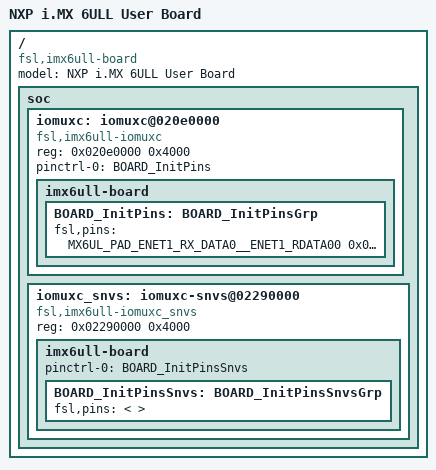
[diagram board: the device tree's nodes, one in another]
/***********************************************************************************************************************
 * This file was generated by the MCUXpresso Config Tools. Any manual edits made to this file
 * will be overwritten if the respective MCUXpresso Config Tools is used to update this file.
 **********************************************************************************************************************/

/*
 * TEXT BELOW IS USED AS SETTING FOR TOOLS *************************************
!!GlobalInfo
product: Pins v12.0
processor: MCIMX6Y2xxx08
package_id: MCIMX6Y2CVM08
mcu_data: i_mx_2_0
processor_version: 12.0.0
 * BE CAREFUL MODIFYING THIS COMMENT - IT IS YAML SETTINGS FOR TOOLS ***********
 */

/*
 * TEXT BELOW IS USED AS SETTING FOR TOOLS *************************************
BOARD_InitPins:
- options: {callFromInitBoot: 'false', coreID: ca7}
- pin_list:
  - {pin_num: L5, peripheral: MMDC, signal: 'mmdc_addr, 0', pin_signal: DRAM_ADDR00}
  - {pin_num: H2, peripheral: MMDC, signal: 'mmdc_addr, 1', pin_signal: DRAM_ADDR01}
  - {pin_num: K1, peripheral: MMDC, signal: 'mmdc_addr, 2', pin_signal: DRAM_ADDR02}
  - {pin_num: M2, peripheral: MMDC, signal: 'mmdc_addr, 3', pin_signal: DRAM_ADDR03}
  - {pin_num: K4, peripheral: MMDC, signal: 'mmdc_addr, 4', pin_signal: DRAM_ADDR04}
  - {pin_num: L1, peripheral: MMDC, signal: 'mmdc_addr, 5', pin_signal: DRAM_ADDR05}
  - {pin_num: G2, peripheral: MMDC, signal: 'mmdc_addr, 6', pin_signal: DRAM_ADDR06}
  - {pin_num: H4, peripheral: MMDC, signal: 'mmdc_addr, 7', pin_signal: DRAM_ADDR07}
  - {pin_num: J4, peripheral: MMDC, signal: 'mmdc_addr, 8', pin_signal: DRAM_ADDR08}
  - {pin_num: L2, peripheral: MMDC, signal: 'mmdc_addr, 9', pin_signal: DRAM_ADDR09}
  - {pin_num: M4, peripheral: MMDC, signal: 'mmdc_addr, 10', pin_signal: DRAM_ADDR10}
  - {pin_num: K3, peripheral: MMDC, signal: 'mmdc_addr, 11', pin_signal: DRAM_ADDR11}
  - {pin_num: L4, peripheral: MMDC, signal: 'mmdc_addr, 12', pin_signal: DRAM_ADDR12}
  - {pin_num: H3, peripheral: MMDC, signal: 'mmdc_addr, 13', pin_signal: DRAM_ADDR13}
  - {pin_num: G1, peripheral: MMDC, signal: 'mmdc_addr, 14', pin_signal: DRAM_ADDR14}
  - {pin_num: K5, peripheral: MMDC, signal: 'mmdc_addr, 15', pin_signal: DRAM_ADDR15}
  - {pin_num: J2, peripheral: MMDC, signal: mmdc_cas_b, pin_signal: DRAM_CAS_B}
  - {pin_num: N2, peripheral: MMDC, signal: mmdc_cs0_b, pin_signal: DRAM_CS0_B}
  - {pin_num: H5, peripheral: MMDC, signal: mmdc_cs1_b, pin_signal: DRAM_CS1_B}
  - {pin_num: T4, peripheral: MMDC, signal: 'mmdc_data, 0', pin_signal: DRAM_DATA00}
  - {pin_num: U6, peripheral: MMDC, signal: 'mmdc_data, 1', pin_signal: DRAM_DATA01}
  - {pin_num: T6, peripheral: MMDC, signal: 'mmdc_data, 2', pin_signal: DRAM_DATA02}
  - {pin_num: U7, peripheral: MMDC, signal: 'mmdc_data, 3', pin_signal: DRAM_DATA03}
  - {pin_num: U8, peripheral: MMDC, signal: 'mmdc_data, 4', pin_signal: DRAM_DATA04}
  - {pin_num: T8, peripheral: MMDC, signal: 'mmdc_data, 5', pin_signal: DRAM_DATA05}
  - {pin_num: T5, peripheral: MMDC, signal: 'mmdc_data, 6', pin_signal: DRAM_DATA06}
  - {pin_num: U4, peripheral: MMDC, signal: 'mmdc_data, 7', pin_signal: DRAM_DATA07}
  - {pin_num: U2, peripheral: MMDC, signal: 'mmdc_data, 8', pin_signal: DRAM_DATA08}
  - {pin_num: U3, peripheral: MMDC, signal: 'mmdc_data, 9', pin_signal: DRAM_DATA09}
  - {pin_num: U5, peripheral: MMDC, signal: 'mmdc_data, 10', pin_signal: DRAM_DATA10}
  - {pin_num: R4, peripheral: MMDC, signal: 'mmdc_data, 11', pin_signal: DRAM_DATA11}
  - {pin_num: P5, peripheral: MMDC, signal: 'mmdc_data, 12', pin_signal: DRAM_DATA12}
  - {pin_num: P3, peripheral: MMDC, signal: 'mmdc_data, 13', pin_signal: DRAM_DATA13}
  - {pin_num: R2, peripheral: MMDC, signal: 'mmdc_data, 14', pin_signal: DRAM_DATA14}
  - {pin_num: R1, peripheral: MMDC, signal: 'mmdc_data, 15', pin_signal: DRAM_DATA15}
  - {pin_num: T7, peripheral: MMDC, signal: 'mmdc_dqm, 0', pin_signal: DRAM_DQM0}
  - {pin_num: T3, peripheral: MMDC, signal: 'mmdc_dqm, 1', pin_signal: DRAM_DQM1}
  - {pin_num: N1, peripheral: MMDC, signal: 'mmdc_odt, 0', pin_signal: DRAM_ODT0}
  - {pin_num: F1, peripheral: MMDC, signal: 'mmdc_odt, 1', pin_signal: DRAM_ODT1}
  - {pin_num: M5, peripheral: MMDC, signal: mmdc_ras_b, pin_signal: DRAM_RAS_B}
  - {pin_num: G4, peripheral: MMDC, signal: mmdc_reset, pin_signal: DRAM_RESET}
  - {pin_num: M1, peripheral: MMDC, signal: 'mmdc_sdba, 0', pin_signal: DRAM_SDBA0}
  - {pin_num: H1, peripheral: MMDC, signal: 'mmdc_sdba, 1', pin_signal: DRAM_SDBA1}
  - {pin_num: K2, peripheral: MMDC, signal: 'mmdc_sdba, 2', pin_signal: DRAM_SDBA2}
  - {pin_num: M3, peripheral: MMDC, signal: 'mmdc_sdcke, 0', pin_signal: DRAM_SDCKE0}
  - {pin_num: J3, peripheral: MMDC, signal: 'mmdc_sdcke, 1', pin_signal: DRAM_SDCKE1}
  - {pin_num: P2, peripheral: MMDC, signal: mmdc_sdclk0_n, pin_signal: DRAM_SDCLK0_N}
  - {pin_num: P1, peripheral: MMDC, signal: mmdc_sdclk0_p, pin_signal: DRAM_SDCLK0_P}
  - {pin_num: P7, peripheral: MMDC, signal: mmdc_sdqs0_n, pin_signal: DRAM_SDQS0_N}
  - {pin_num: P6, peripheral: MMDC, signal: mmdc_sdqs0_p, pin_signal: DRAM_SDQS0_P}
  - {pin_num: T2, peripheral: MMDC, signal: mmdc_sdqs1_n, pin_signal: DRAM_SDQS1_N}
  - {pin_num: T1, peripheral: MMDC, signal: mmdc_sdqs1_p, pin_signal: DRAM_SDQS1_P}
  - {pin_num: J1, peripheral: MMDC, signal: mmdc_sdwe_b, pin_signal: DRAM_SDWE_B}
  - {pin_num: C17, peripheral: ENET1, signal: enet_mdio, pin_signal: ENET2_RX_DATA0}
  - {pin_num: C16, peripheral: ENET1, signal: enet_mdc, pin_signal: ENET2_RX_DATA1}
  - {pin_num: F15, peripheral: ENET1, signal: enet_tx_en, pin_signal: ENET1_TX_EN}
  - {pin_num: E14, peripheral: ENET1, signal: 'enet_tdata, 1', pin_signal: ENET1_TX_DATA1}
  - {pin_num: E15, peripheral: ENET1, signal: 'enet_tdata, 0', pin_signal: ENET1_TX_DATA0}
  - {pin_num: F14, peripheral: ENET1, signal: 'enet_ref_clk, 1', pin_signal: ENET1_TX_CLK}
  - {pin_num: D15, peripheral: ENET1, signal: enet_rx_er, pin_signal: ENET1_RX_ER}
  - {pin_num: E17, peripheral: ENET1, signal: 'enet_rdata, 1', pin_signal: ENET1_RX_DATA1}
  - {pin_num: F16, peripheral: ENET1, signal: 'enet_rdata, 0', pin_signal: ENET1_RX_DATA0}
  - {pin_num: B17, peripheral: ENET1, signal: enet_ref_clk_25m, pin_signal: ENET2_RX_EN}
  - {pin_num: K15, peripheral: ENET1, signal: enet_rx_clk, pin_signal: UART1_CTS_B}
  - {pin_num: A15, peripheral: GPIO2, signal: 'gpio_io, 11', pin_signal: ENET2_TX_DATA0}
  - {pin_num: D7, peripheral: uSDHC2, signal: 'usdhc_data, 0', pin_signal: NAND_DATA00}
  - {pin_num: B7, peripheral: uSDHC2, signal: 'usdhc_data, 1', pin_signal: NAND_DATA01}
  - {pin_num: A7, peripheral: uSDHC2, signal: 'usdhc_data, 2', pin_signal: NAND_DATA02}
  - {pin_num: D6, peripheral: uSDHC2, signal: 'usdhc_data, 3', pin_signal: NAND_DATA03}
  - {pin_num: D8, peripheral: uSDHC2, signal: usdhc_clk, pin_signal: NAND_RE_B}
  - {pin_num: C8, peripheral: uSDHC2, signal: usdhc_cmd, pin_signal: NAND_WE_B}
  - {pin_num: B3, peripheral: uSDHC1, signal: 'usdhc_data, 0', pin_signal: SD1_DATA0}
  - {pin_num: B2, peripheral: uSDHC1, signal: 'usdhc_data, 1', pin_signal: SD1_DATA1}
  - {pin_num: B1, peripheral: uSDHC1, signal: 'usdhc_data, 2', pin_signal: SD1_DATA2}
  - {pin_num: A2, peripheral: uSDHC1, signal: 'usdhc_data, 3', pin_signal: SD1_DATA3}
  - {pin_num: C2, peripheral: uSDHC1, signal: usdhc_cmd, pin_signal: SD1_CMD}
  - {pin_num: C1, peripheral: uSDHC1, signal: usdhc_clk, pin_signal: SD1_CLK}
  - {pin_num: A3, peripheral: GPIO4, signal: 'gpio_io, 12', pin_signal: NAND_READY_B}
 * BE CAREFUL MODIFYING THIS COMMENT - IT IS YAML SETTINGS FOR TOOLS ***********
 */

/dts-v1/;

#include "skeleton.dtsi"
#include "imx6ull-pinfunc.h"
#include "imx6ull-pinfunc-snvs.h"

/ {
    model = "NXP i.MX 6ULL User Board";
    compatible = "fsl,imx6ull-board", "fsl,imx6ull";

    soc {
        #address-cells = <1>;
        #size-cells = <1>;

        iomuxc: iomuxc@020e0000 {
            compatible = "fsl,imx6ull-iomuxc";
            reg = <0x020e0000 0x4000>;
        };

        iomuxc_snvs: iomuxc-snvs@02290000 {
            compatible = "fsl,imx6ull-iomuxc_snvs";
            reg = <0x02290000 0x4000>;
        };
    };
};

&iomuxc {
    pinctrl-names = "default";
    pinctrl-0 = <&BOARD_InitPins>;
    imx6ull-board {
        BOARD_InitPins: BOARD_InitPinsGrp {                /*!< Function assigned for the core: Cortex-A7[ca7] */
            fsl,pins = <
                MX6UL_PAD_ENET1_RX_DATA0__ENET1_RDATA00    0x000010B0
                MX6UL_PAD_ENET1_RX_DATA1__ENET1_RDATA01    0x000010B0
                MX6UL_PAD_ENET1_RX_ER__ENET1_RX_ER         0x000010B0
                MX6UL_PAD_ENET1_TX_CLK__ENET1_REF_CLK1     0x000010B0
                MX6UL_PAD_ENET1_TX_DATA0__ENET1_TDATA00    0x000010B0
                MX6UL_PAD_ENET1_TX_DATA1__ENET1_TDATA01    0x000010B0
                MX6UL_PAD_ENET1_TX_EN__ENET1_TX_EN         0x000010B0
                MX6UL_PAD_ENET2_RX_DATA0__ENET1_MDIO       0x000010B0
                MX6UL_PAD_ENET2_RX_DATA1__ENET1_MDC        0x000010B0
                MX6UL_PAD_ENET2_RX_EN__ENET1_REF_CLK_25M   0x000010B0
                MX6UL_PAD_ENET2_TX_DATA0__GPIO2_IO11       0x000010B0
                MX6UL_PAD_NAND_DATA00__USDHC2_DATA0        0x000010B0
                MX6UL_PAD_NAND_DATA01__USDHC2_DATA1        0x000010B0
                MX6UL_PAD_NAND_DATA02__USDHC2_DATA2        0x000010B0
                MX6UL_PAD_NAND_DATA03__USDHC2_DATA3        0x000010B0
                MX6UL_PAD_NAND_READY_B__GPIO4_IO12         0x000010B0
                MX6UL_PAD_NAND_RE_B__USDHC2_CLK            0x000010B0
                MX6UL_PAD_NAND_WE_B__USDHC2_CMD            0x000010B0
                MX6UL_PAD_SD1_CLK__USDHC1_CLK              0x000010B0
                MX6UL_PAD_SD1_CMD__USDHC1_CMD              0x000010B0
                MX6UL_PAD_SD1_DATA0__USDHC1_DATA0          0x000010B0
                MX6UL_PAD_SD1_DATA1__USDHC1_DATA1          0x000010B0
                MX6UL_PAD_SD1_DATA2__USDHC1_DATA2          0x000010B0
                MX6UL_PAD_SD1_DATA3__USDHC1_DATA3          0x000010B0
                MX6UL_PAD_UART1_CTS_B__ENET1_RX_CLK        0x000010B0
            >;
        };
    };
};

&iomuxc_snvs {
    pinctrl-names = "default_snvs";
    imx6ull-board {
    pinctrl-0 = <&BOARD_InitPinsSnvs>;
        BOARD_InitPinsSnvs: BOARD_InitPinsSnvsGrp {        /*!< Function assigned for the core: Cortex-A7[ca7] */
            fsl,pins = <
            >;
        };
    };
};

